# BL808 register map
Vendor: Bouffalo Lab; File version: 0.1
Registers are 32-bit, read-write, reset 0x0 unless marked. A register's access mark holds for its fields unless they carry their own. Offsets are from the block's base; [hi:lo] are bit positions; {n}, {i} and the like mark numbered series; 'fields as' and 'values as' point back to an identical list.

## SDH — Secure Digital host control
Base 0x20060000
0x00 sd_sys_addr_low 16-bit — System Address Low Register
  [15:0] dma_addr_l
0x02 sd_sys_addr_high 16-bit — System Address High Register
  [15:0] dma_addr_h
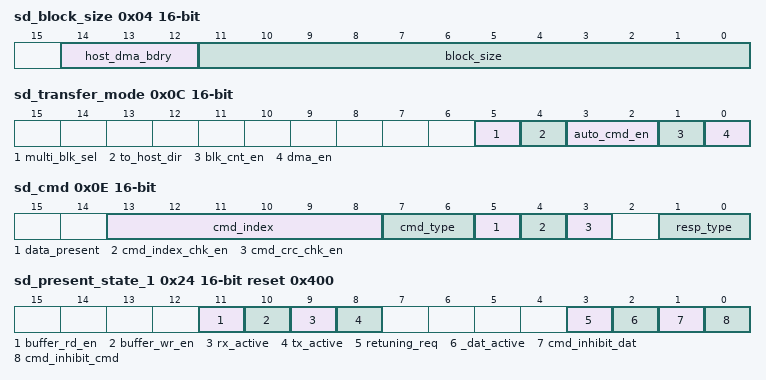
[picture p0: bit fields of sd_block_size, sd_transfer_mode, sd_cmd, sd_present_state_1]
0x04 sd_block_size 16-bit — Block Size Register
  [14:12] host_dma_bdry, [11:0] block_size
0x06 sd_block_count 16-bit — Block Count Register
  [15:0] block_count
0x08 sd_arg_low 16-bit — Argument Low Register
  [15:0] arg_l
0x0A sd_arg_high 16-bit — Argument High Register
  [15:0] arg_h
0x0C sd_transfer_mode 16-bit — Transfer Mode Register
  [5] multi_blk_sel, [4] to_host_dir, [3:2] auto_cmd_en, [1] blk_cnt_en, [0] dma_en
0x0E sd_cmd 16-bit — Command Register
  [13:8] cmd_index, [7:6] cmd_type, [5] data_present, [4] cmd_index_chk_en, [3] cmd_crc_chk_en, [1:0] resp_type
{0x10+2i} sd_resp_{i} 16-bit (i=0..7) — Response Register {i}
  [15:0] resp{i} ro
0x20 sd_buffer_data_port_0 16-bit — Buffer Data Port 0 Register
  [15:0] cpu_data0
0x22 sd_buffer_data_port_1 16-bit — Buffer Data Port 1 Register
  [15:0] cpu_data1
0x24 sd_present_state_1 16-bit reset 0x400 — Present State Register 1
  [11] buffer_rd_en ro, [10] buffer_wr_en ro, [9] rx_active ro, [8] tx_active ro, [3] retuning_req ro, [2] _dat_active ro, [1] cmd_inhibit_dat ro, [0] cmd_inhibit_cmd ro
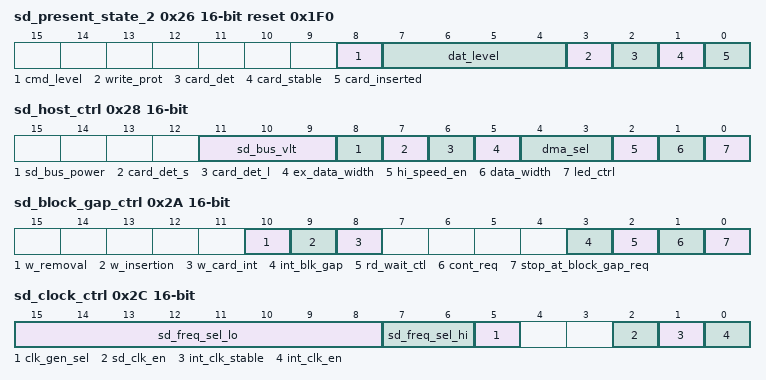
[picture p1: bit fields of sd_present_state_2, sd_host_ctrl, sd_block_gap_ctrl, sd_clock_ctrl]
0x26 sd_present_state_2 16-bit reset 0x1F0 — Present State Register 2
  [8] cmd_level ro, [7:4] dat_level ro, [3] write_prot ro, [2] card_det ro, [1] card_stable ro, [0] card_inserted ro
0x28 sd_host_ctrl 16-bit — Host Control Register
  [11:9] sd_bus_vlt, [8] sd_bus_power, [7] card_det_s, [6] card_det_l, [5] ex_data_width, [4:3] dma_sel, [2] hi_speed_en, [1] data_width, [0] led_ctrl
0x2A sd_block_gap_ctrl 16-bit — Block Gap Control Register
  [10] w_removal, [9] w_insertion, [8] w_card_int, [3] int_blk_gap, [2] rd_wait_ctl, [1] cont_req, [0] stop_at_block_gap_req
0x2C sd_clock_ctrl 16-bit — Clock Control Register
  [15:8] sd_freq_sel_lo, [7:6] sd_freq_sel_hi, [5] clk_gen_sel, [2] sd_clk_en, [1] int_clk_stable ro, [0] int_clk_en
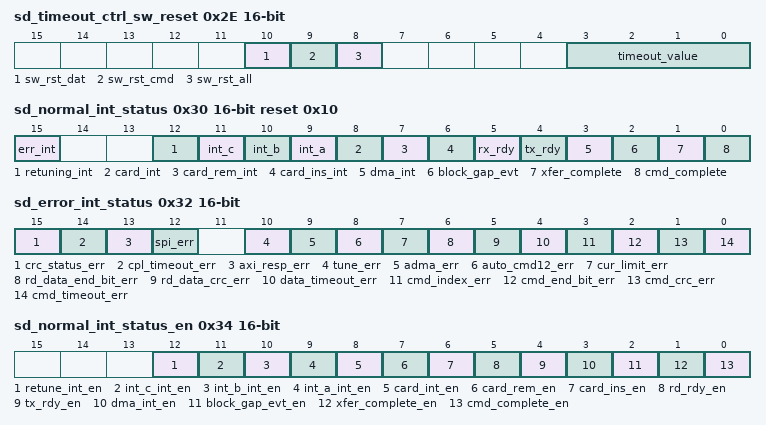
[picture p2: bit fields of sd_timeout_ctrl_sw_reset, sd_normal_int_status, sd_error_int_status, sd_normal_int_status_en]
0x2E sd_timeout_ctrl_sw_reset 16-bit — Timeout Control/Software Reset Register
  [10] sw_rst_dat, [9] sw_rst_cmd, [8] sw_rst_all, [3:0] timeout_value
0x30 sd_normal_int_status 16-bit reset 0x10 — Normal Interrupt Status Register
  [15] err_int ro, [12] retuning_int, [11] int_c, [10] int_b, [9] int_a, [8] card_int ro, [7] card_rem_int, [6] card_ins_int, [5] rx_rdy, [4] tx_rdy, [3] dma_int, [2] block_gap_evt, [1] xfer_complete, [0] cmd_complete
0x32 sd_error_int_status 16-bit — Error Interrupt Status Register
  [15] crc_status_err, [14] cpl_timeout_err, [13] axi_resp_err, [12] spi_err, [10] tune_err, [9] adma_err, [8] auto_cmd12_err, [7] cur_limit_err, [6] rd_data_end_bit_err, [5] rd_data_crc_err, [4] data_timeout_err, [3] cmd_index_err, [2] cmd_end_bit_err, [1] cmd_crc_err, [0] cmd_timeout_err
0x34 sd_normal_int_status_en 16-bit — Normal Interrupt Status Enable Register
  [12] retune_int_en, [11] int_c_int_en, [10] int_b_int_en, [9] int_a_int_en, [8] card_int_en, [7] card_rem_en, [6] card_ins_en, [5] rd_rdy_en, [4] tx_rdy_en, [3] dma_int_en, [2] block_gap_evt_en, [1] xfer_complete_en, [0] cmd_complete_en
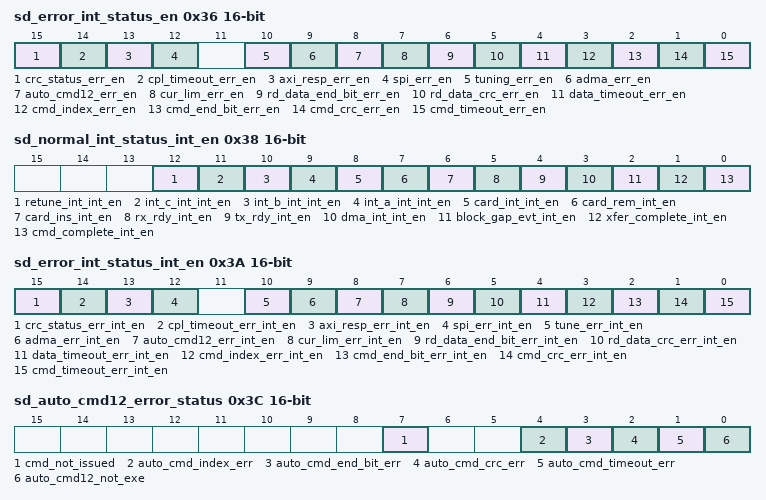
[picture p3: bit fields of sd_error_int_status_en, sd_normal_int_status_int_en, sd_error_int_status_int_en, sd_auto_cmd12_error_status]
0x36 sd_error_int_status_en 16-bit — Error Interrupt Status Enable Register
  [15] crc_status_err_en, [14] cpl_timeout_err_en, [13] axi_resp_err_en, [12] spi_err_en, [10] tuning_err_en, [9] adma_err_en, [8] auto_cmd12_err_en, [7] cur_lim_err_en, [6] rd_data_end_bit_err_en, [5] rd_data_crc_err_en, [4] data_timeout_err_en, [3] cmd_index_err_en, [2] cmd_end_bit_err_en, [1] cmd_crc_err_en, [0] cmd_timeout_err_en
0x38 sd_normal_int_status_int_en 16-bit — Normal Interrupt Status Interrupt Enable Register
  [12] retune_int_int_en, [11] int_c_int_int_en, [10] int_b_int_int_en, [9] int_a_int_int_en, [8] card_int_int_en, [7] card_rem_int_en, [6] card_ins_int_en, [5] rx_rdy_int_en, [4] tx_rdy_int_en, [3] dma_int_int_en, [2] block_gap_evt_int_en, [1] xfer_complete_int_en, [0] cmd_complete_int_en
0x3A sd_error_int_status_int_en 16-bit — Error Interrupt Status Interrupt Enable Register
  [15] crc_status_err_int_en, [14] cpl_timeout_err_int_en, [13] axi_resp_err_int_en, [12] spi_err_int_en, [10] tune_err_int_en, [9] adma_err_int_en, [8] auto_cmd12_err_int_en, [7] cur_lim_err_int_en, [6] rd_data_end_bit_err_int_en, [5] rd_data_crc_err_int_en, [4] data_timeout_err_int_en, [3] cmd_index_err_int_en, [2] cmd_end_bit_err_int_en, [1] cmd_crc_err_int_en, [0] cmd_timeout_err_int_en
0x3C sd_auto_cmd12_error_status 16-bit — Auto CMD12 Error Status Register
  [7] cmd_not_issued ro, [4] auto_cmd_index_err, [3] auto_cmd_end_bit_err, [2] auto_cmd_crc_err, [1] auto_cmd_timeout_err, [0] auto_cmd12_not_exe
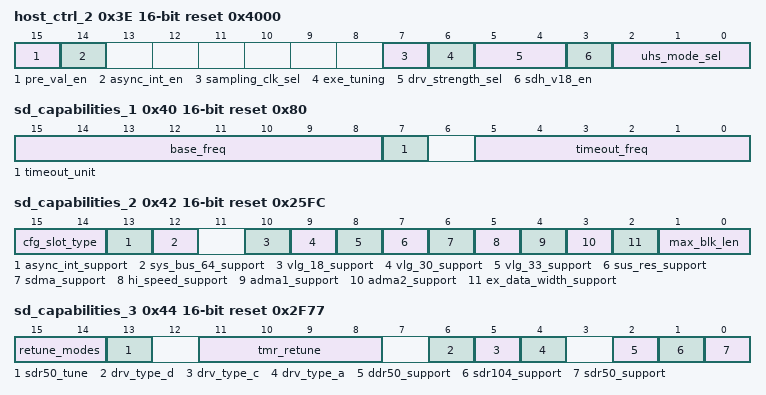
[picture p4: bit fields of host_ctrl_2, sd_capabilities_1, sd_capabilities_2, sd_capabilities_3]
0x3E host_ctrl_2 16-bit reset 0x4000 — Host Control 2 Register
  [15] pre_val_en, [14] async_int_en, [7] sampling_clk_sel, [6] exe_tuning, [5:4] drv_strength_sel, [3] sdh_v18_en, [2:0] uhs_mode_sel
0x40 sd_capabilities_1 16-bit reset 0x80 — Capabilities Register 1
  [15:8] base_freq ro, [7] timeout_unit ro, [5:0] timeout_freq ro
0x42 sd_capabilities_2 16-bit reset 0x25FC — Capabilities Register 2
  [15:14] cfg_slot_type, [13] async_int_support ro, [12] sys_bus_64_support ro, [10] vlg_18_support ro, [9] vlg_30_support ro, [8] vlg_33_support ro, [7] sus_res_support ro, [6] sdma_support ro, [5] hi_speed_support ro, [4] adma1_support ro, [3] adma2_support ro, [2] ex_data_width_support ro, [1:0] max_blk_len ro
0x44 sd_capabilities_3 16-bit reset 0x2F77 — Capabilities Register 3
  [15:14] retune_modes ro, [13] sdr50_tune ro, [11:8] tmr_retune ro, [6] drv_type_d ro, [5] drv_type_c ro, [4] drv_type_a ro, [2] ddr50_support ro, [1] sdr104_support ro, [0] sdr50_support ro
0x46 sd_capabilities_4 16-bit — Capabilities Register 4
  [7:0] clk_multiplier ro
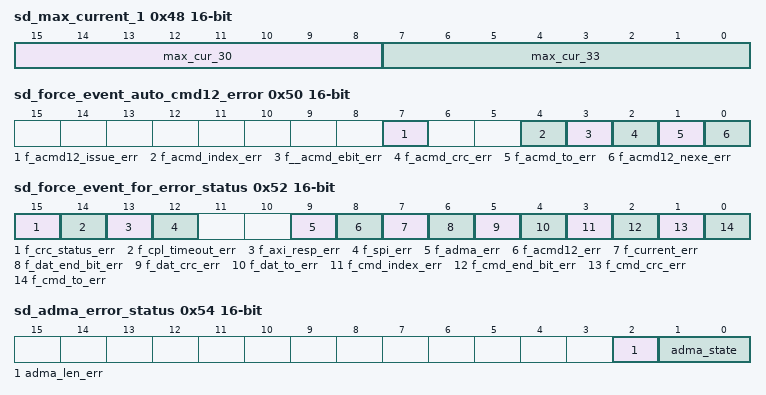
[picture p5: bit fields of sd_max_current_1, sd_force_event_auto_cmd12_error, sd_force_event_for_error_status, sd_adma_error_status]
0x48 sd_max_current_1 16-bit — Maximum Current Register 1
  [15:8] max_cur_30 ro, [7:0] max_cur_33 ro
0x4A sd_max_current_2 16-bit — Maximum Current Register 2
  [7:0] max_cur_18 ro
0x4C sd_max_current_3 16-bit — Maximum Current Register 3
0x4E sd_max_current_4 16-bit — Maximum Current Register 4
0x50 sd_force_event_auto_cmd12_error 16-bit — Force Event Auto cmd12 Error Register
  [7] f_acmd12_issue_err wo, [4] f_acmd_index_err wo, [3] f__acmd_ebit_err wo, [2] f_acmd_crc_err wo, [1] f_acmd_to_err wo, [0] f_acmd12_nexe_err wo
0x52 sd_force_event_for_error_status 16-bit — Force Event for Error Status Register
  [15] f_crc_status_err wo, [14] f_cpl_timeout_err wo, [13] f_axi_resp_err wo, [12] f_spi_err wo, [9] f_adma_err wo, [8] f_acmd12_err wo, [7] f_current_err wo, [6] f_dat_end_bit_err wo, [5] f_dat_crc_err wo, [4] f_dat_to_err wo, [3] f_cmd_index_err wo, [2] f_cmd_end_bit_err wo, [1] f_cmd_crc_err wo, [0] f_cmd_to_err wo
0x54 sd_adma_error_status 16-bit — ADMA Error Status Register
  [2] adma_len_err, [1:0] adma_state
{0x56+2i} sd_adma_sys_addr_{i} 16-bit (i=1..4) — ADMA System Address Register {i}
  [15:0] adma_sys_addr
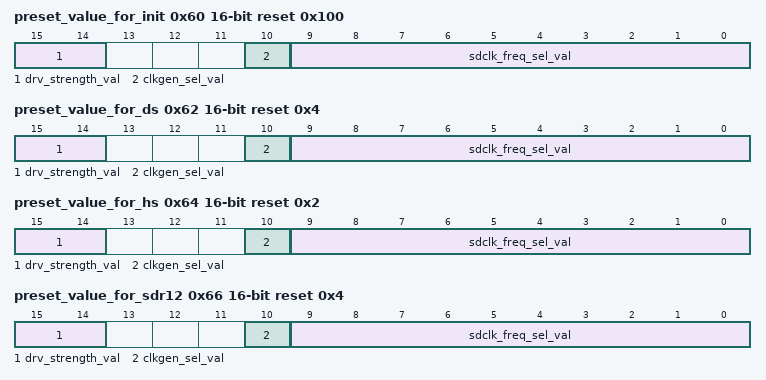
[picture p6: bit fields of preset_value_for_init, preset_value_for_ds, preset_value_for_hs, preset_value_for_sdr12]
0x60 preset_value_for_init 16-bit reset 0x100 — Preset Value Register for Initialization
  [15:14] drv_strength_val ro, [10] clkgen_sel_val ro, [9:0] sdclk_freq_sel_val ro
0x62 preset_value_for_ds 16-bit reset 0x4 — Preset Value Register for Default Speed
  fields as preset_value_for_init
0x64 preset_value_for_hs 16-bit reset 0x2 — Preset Value Register for High Speed
  fields as preset_value_for_init
0x66 preset_value_for_sdr12 16-bit reset 0x4 — Preset Value Register for SDR12
  fields as preset_value_for_init
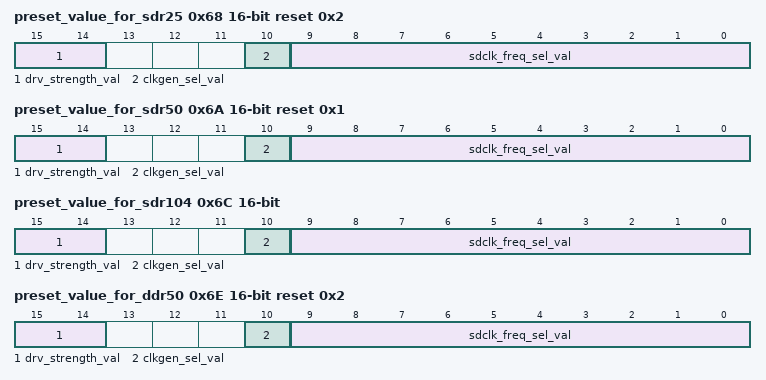
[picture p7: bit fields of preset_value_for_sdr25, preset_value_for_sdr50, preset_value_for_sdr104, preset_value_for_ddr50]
0x68 preset_value_for_sdr25 16-bit reset 0x2 — Preset Value Register for SDR25
  fields as preset_value_for_init
0x6A preset_value_for_sdr50 16-bit reset 0x1 — Preset Value Register for SDR50
  fields as preset_value_for_init
0x6C preset_value_for_sdr104 16-bit — Preset Value Register for SDR104
  fields as preset_value_for_init
0x6E preset_value_for_ddr50 16-bit reset 0x2 — Preset Value Register for DDR50
  fields as preset_value_for_init
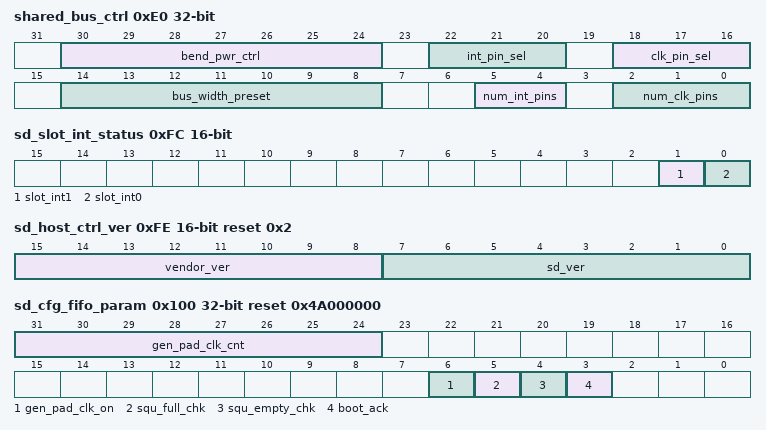
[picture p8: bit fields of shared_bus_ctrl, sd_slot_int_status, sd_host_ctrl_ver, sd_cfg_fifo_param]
0xE0 shared_bus_ctrl — Shared Bus Control Register
  [30:24] bend_pwr_ctrl, [22:20] int_pin_sel, [18:16] clk_pin_sel, [14:8] bus_width_preset ro, [5:4] num_int_pins ro, [2:0] num_clk_pins ro
0xFC sd_slot_int_status 16-bit — Slot Interrupt Status Register
  [1] slot_int1 ro, [0] slot_int0 ro
0xFE sd_host_ctrl_ver 16-bit reset 0x2 — Host Control Version Register
  [15:8] vendor_ver ro, [7:0] sd_ver ro
0x100 sd_cfg_fifo_param reset 0x4A000000 — SD Extra Parameters Register
  [31:24] gen_pad_clk_cnt, [6] gen_pad_clk_on, [5] squ_full_chk, [4] squ_empty_chk, [3] boot_ack
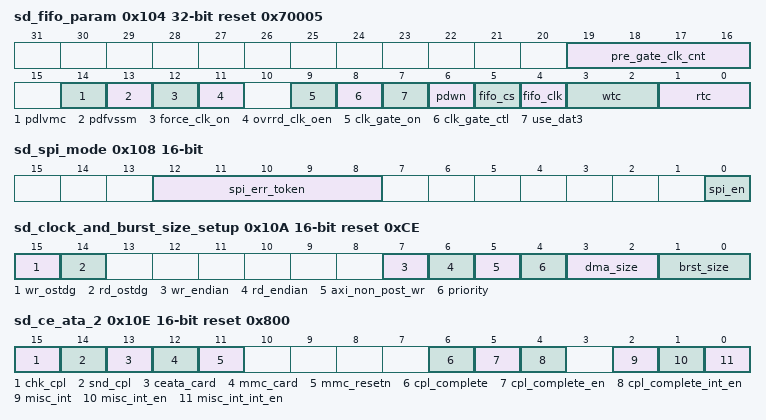
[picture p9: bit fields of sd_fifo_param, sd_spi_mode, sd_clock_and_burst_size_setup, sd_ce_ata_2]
0x104 sd_fifo_param reset 0x70005 — FIFO Parameters Register
  [19:16] pre_gate_clk_cnt, [14] pdlvmc, [13] pdfvssm, [12] force_clk_on, [11] ovrrd_clk_oen, [9] clk_gate_on, [8] clk_gate_ctl, [7] use_dat3, [6] pdwn, [5] fifo_cs, [4] fifo_clk, [3:2] wtc, [1:0] rtc
0x108 sd_spi_mode 16-bit — SPI Mode Register
  [12:8] spi_err_token, [0] spi_en
0x10A sd_clock_and_burst_size_setup 16-bit reset 0xCE — Clock and Burst Size Setup Register
  [15] wr_ostdg, [14] rd_ostdg, [7] wr_endian, [6] rd_endian, [5] axi_non_post_wr, [4] priority, [3:2] dma_size, [1:0] brst_size
0x10C sd_ce_ata_1 16-bit reset 0x3FFF — CE-ATA Register 1
  [13:0] cpl_timeout
0x10E sd_ce_ata_2 16-bit reset 0x800 — CE-ATA Register 2
  [15] chk_cpl, [14] snd_cpl, [13] ceata_card, [12] mmc_card, [11] mmc_resetn, [6] cpl_complete, [5] cpl_complete_en, [4] cpl_complete_int_en, [2] misc_int, [1] misc_int_en, [0] misc_int_int_en
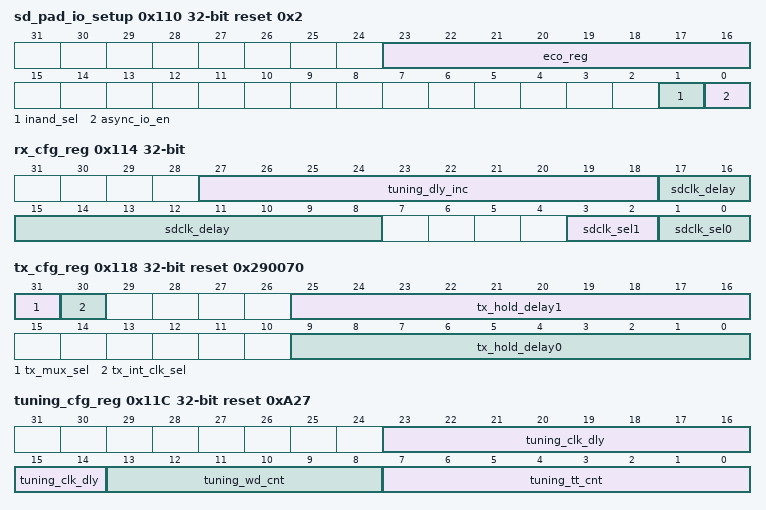
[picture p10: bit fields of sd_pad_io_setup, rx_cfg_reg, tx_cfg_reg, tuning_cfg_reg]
0x110 sd_pad_io_setup reset 0x2 — PAD I/O Setup Register
  [23:16] eco_reg, [1] inand_sel, [0] async_io_en
0x114 rx_cfg_reg — RX Configuration Register
  [27:18] tuning_dly_inc, [17:8] sdclk_delay, [3:2] sdclk_sel1, [1:0] sdclk_sel0
0x118 tx_cfg_reg reset 0x290070 — TX Configuration Register
  [31] tx_mux_sel, [30] tx_int_clk_sel, [25:16] tx_hold_delay1, [9:0] tx_hold_delay0
0x11C tuning_cfg_reg reset 0xA27 — TUNING CONFIG Register
  [23:14] tuning_clk_dly ro, [13:8] tuning_wd_cnt, [7:0] tuning_tt_cnt
